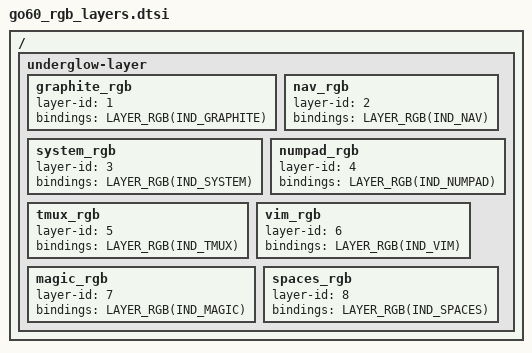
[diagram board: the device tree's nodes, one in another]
/*
 * Per-layer RGB underglow extensions (darknao/zmk PR36).
 *
 * Included from both go60_lh.keymap and go60_rh.keymap (build.yaml targets
 * `go60_lh` and `go60_rh` directly; go60.keymap is unused).
 *
 * Lights two corner LEDs (LH outer-top = pos 0, RH outer-top = pos 11)
 * a distinct colour per active layer. Base layer = no painting (off).
 *
 *   Layer 1 Graphite : cyan
 *   Layer 2 Nav      : green
 *   Layer 3 System   : red
 *   Layer 4 Numpad   : yellow
 *   Layer 5 Tmux     : magenta
 *   Layer 6 Vim      : orange
 *   Layer 7 Magic    : white
 *   Layer 8 Spaces   : blue
 *
 * &ug takes one cell: a 24-bit 0xRRGGBB value. &trans falls through
 * to the next active layer's binding (so highest active layer wins).
 *
 * To activate after first flash: hold Magic (RH T2), tap RGB_TOG (T-key
 * position) to enable RGB, then tap RGB_EFF to cycle to the layer-
 * indicators effect (one cycle from SWIRL). CONFIG_SETTINGS persists
 * both across reboots.
 */

#define IND_GRAPHITE  0x00FFFF
#define IND_NAV       0x00FF00
#define IND_SYSTEM    0xFF0000
#define IND_NUMPAD    0xFFFF00
#define IND_TMUX      0xFF00FF
#define IND_VIM       0xFF8000
#define IND_MAGIC     0xFFFFFF
#define IND_SPACES    0x0000FF

/* 60-entry bindings array: indicator at LH outer-top (0) and RH outer-top (11), trans elsewhere. */
#define LAYER_RGB(color)                                                                          \
  <&ug color>, <&trans>, <&trans>, <&trans>, <&trans>, <&trans>,                                  \
  <&trans>, <&trans>, <&trans>, <&trans>, <&trans>, <&ug color>,                                  \
  <&trans>, <&trans>, <&trans>, <&trans>, <&trans>, <&trans>,                                     \
  <&trans>, <&trans>, <&trans>, <&trans>, <&trans>, <&trans>,                                     \
  <&trans>, <&trans>, <&trans>, <&trans>, <&trans>, <&trans>,                                     \
  <&trans>, <&trans>, <&trans>, <&trans>, <&trans>, <&trans>,                                     \
  <&trans>, <&trans>, <&trans>, <&trans>, <&trans>, <&trans>,                                     \
  <&trans>, <&trans>, <&trans>, <&trans>, <&trans>, <&trans>,                                     \
  <&trans>, <&trans>, <&trans>, <&trans>, <&trans>, <&trans>,                                     \
  <&trans>, <&trans>, <&trans>, <&trans>, <&trans>

/ {
    underglow-layer {
        graphite_rgb { layer-id = <1>; bindings = LAYER_RGB(IND_GRAPHITE); };
        nav_rgb      { layer-id = <2>; bindings = LAYER_RGB(IND_NAV);      };
        system_rgb   { layer-id = <3>; bindings = LAYER_RGB(IND_SYSTEM);   };
        numpad_rgb   { layer-id = <4>; bindings = LAYER_RGB(IND_NUMPAD);   };
        tmux_rgb     { layer-id = <5>; bindings = LAYER_RGB(IND_TMUX);     };
        vim_rgb      { layer-id = <6>; bindings = LAYER_RGB(IND_VIM);      };
        magic_rgb    { layer-id = <7>; bindings = LAYER_RGB(IND_MAGIC);    };
        spaces_rgb   { layer-id = <8>; bindings = LAYER_RGB(IND_SPACES);   };
    };
};
